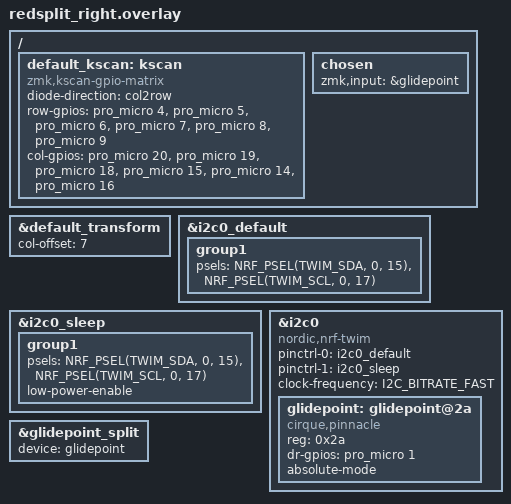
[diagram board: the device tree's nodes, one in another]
#include <dt-bindings/zmk/matrix_transform.h>
#include "redsplit.dtsi"

/ {
  default_kscan: kscan {
    compatible = "zmk,kscan-gpio-matrix";
    diode-direction = "col2row";

    row-gpios = 
                <&pro_micro 4 (GPIO_ACTIVE_HIGH | GPIO_PULL_DOWN)>,
                <&pro_micro 5 (GPIO_ACTIVE_HIGH | GPIO_PULL_DOWN)>,
                <&pro_micro 6 (GPIO_ACTIVE_HIGH | GPIO_PULL_DOWN)>,
                <&pro_micro 7 (GPIO_ACTIVE_HIGH | GPIO_PULL_DOWN)>,
                <&pro_micro 8 (GPIO_ACTIVE_HIGH | GPIO_PULL_DOWN)>,
                <&pro_micro 9 (GPIO_ACTIVE_HIGH | GPIO_PULL_DOWN)>;

    col-gpios = 
                <&pro_micro 20 (GPIO_ACTIVE_HIGH| GPIO_PULL_DOWN)>,
                <&pro_micro 19 (GPIO_ACTIVE_HIGH| GPIO_PULL_DOWN)>, 
                <&pro_micro 18 (GPIO_ACTIVE_HIGH| GPIO_PULL_DOWN)>,
                <&pro_micro 15 (GPIO_ACTIVE_HIGH| GPIO_PULL_DOWN)>,
                <&pro_micro 14 (GPIO_ACTIVE_HIGH| GPIO_PULL_DOWN)>,
                <&pro_micro 16 (GPIO_ACTIVE_HIGH| GPIO_PULL_DOWN)>;
  };

  chosen {
    zmk,input = &glidepoint;
  };
};

&default_transform {
  col-offset = <7>;
};

&i2c0_default {
  group1 {
    psels = <NRF_PSEL(TWIM_SDA, 0, 15)>,
        <NRF_PSEL(TWIM_SCL, 0, 17)>;
  };
};

&i2c0_sleep{
  group1 {
    psels = <NRF_PSEL(TWIM_SDA, 0, 15)>,
        <NRF_PSEL(TWIM_SCL, 0, 17)>;
    low-power-enable;
  };
};

cirque_pinnacle_i2c: &i2c0 {
    compatible = "nordic,nrf-twim";
    pinctrl-0 = <&i2c0_default>;
    pinctrl-1 = <&i2c0_sleep>;
    pinctrl-names = "default", "sleep";
    clock-frequency = <I2C_BITRATE_FAST>;
};

&cirque_pinnacle_i2c {
    status = "okay";

    glidepoint: glidepoint@2a {
        compatible = "cirque,pinnacle";
        reg = <0x2a>;
        status = "okay";
        dr-gpios = <&pro_micro 1 (GPIO_ACTIVE_HIGH)>;
        // sensitivity = "2x";
        // sleep; 
        // no-taps;
        absolute-mode;
    };
};

&glidepoint {
	status = "okay";
};

&glidepoint_split {
	device = <&glidepoint>;
};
